# EFR32MG24A020F1536IM40 register map
Vendor: Silicon Labs; Series: EFR32; File version: B
Registers are 32-bit, read-write, reset 0x0 unless marked. A register's access mark holds for its fields unless they carry their own. Offsets are from the block's base; [hi:lo] are bit positions; {n}, {i} and the like mark numbered series; 'fields as' and 'values as' point back to an identical list.

## MODEM_S (part 2 of 2) — MODEM_S Registers
Base 0xA8014000
Same registers: MODEM_NS 0xB8014000
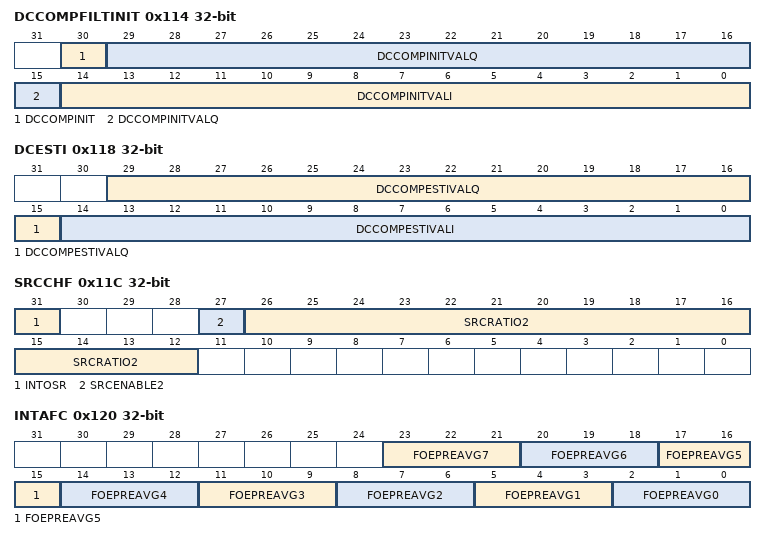
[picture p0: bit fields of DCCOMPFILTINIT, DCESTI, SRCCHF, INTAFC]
0x114 DCCOMPFILTINIT
  [30] DCCOMPINIT — Initialize filter state
  [29:15] DCCOMPINITVALQ — Q-channel initialization value
  [14:0] DCCOMPINITVALI — I-channel initialization value
0x118 DCESTI ro
  [29:15] DCCOMPESTIVALQ — Q-channel DC-Offset Estimated value
  [14:0] DCCOMPESTIVALI — I-channel DC-Offset Estimated value
0x11C SRCCHF
  [31] INTOSR — Forcing Integer OSR
  [27] SRCENABLE2 — SRC2 enable
  [26:12] SRCRATIO2 — SRC2 ratio
0x120 INTAFC
  [23:21] FOEPREAVG7 — Eighth estimate
  [20:18] FOEPREAVG6 — Seventh estimate
  [17:15] FOEPREAVG5 — Sixth estimate
  [14:12] FOEPREAVG4 — Fifth estimate
  [11:9] FOEPREAVG3 — Fourth estimate
  [8:6] FOEPREAVG2 — Third estimate
  [5:3] FOEPREAVG1 — Second estimate
  [2:0] FOEPREAVG0 — First estimate
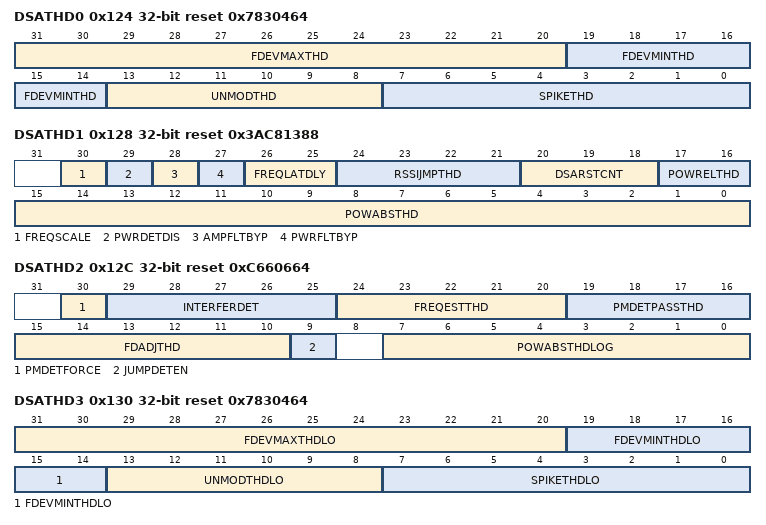
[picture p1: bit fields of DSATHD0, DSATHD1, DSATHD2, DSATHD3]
0x124 DSATHD0 reset 0x7830464
  [31:20] FDEVMAXTHD — Frequency deviation maximum threshold
  [19:14] FDEVMINTHD — Frequency deviation minimum threshold
  [13:8] UNMODTHD — Unmodulated carrier detector threshold
  [7:0] SPIKETHD — Spike threshold
0x128 DSATHD1 reset 0x3AC81388
  [30] FREQSCALE — Frequency scale factor
  [29] PWRDETDIS — Power detection disabled
  [28] AMPFLTBYP — Amplitude filter bypass
  [27] PWRFLTBYP — Power filter bypass
  [26:25] FREQLATDLY — Frequency late delay
  [24:21] RSSIJMPTHD — RSSI jump detector threshold
  [20:18] DSARSTCNT — DSA reset counter
  [17:16] POWRELTHD — Relative power detector threshold
    0=DISABLED (Threshold is 6dB. The relative power detector will trigger when the current RSSI is 6dB stronger than the previously detected RSSI.); 1=MODE1 (Threshold is 9dB. The relative power detector will trigger when the current RSSI is 9dB stronger than the previously detected RSSI.); 2=MODE2 (Threshold is 12dB. The relative power detector will trigger when the current RSSI is 12dB stronger than the previously detected RSSI.); 3=MODE3 (Threshold is 15dB. The relative power detector will trigger when the current RSSI is 15dB stronger than the previously detected RSSI.)
  [15:0] POWABSTHD — Power absolute threshold
0x12C DSATHD2 reset 0xC660664
  [30] PMDETFORCE — Force DSA preamble detector
  [29:25] INTERFERDET — Interference detection threshold
  [24:20] FREQESTTHD — Frequency Estimation Timeout Threshold
  [19:16] PMDETPASSTHD — DSA Preamble detection counter threshold
  [15:10] FDADJTHD — Frequency deviation ripple threshold
  [9] JUMPDETEN — Power jump detection enable
  [7:0] POWABSTHDLOG — Power threshold in logarithm-scale
0x130 DSATHD3 reset 0x7830464
  [31:20] FDEVMAXTHDLO — Frequency deviation maximum threshold
  [19:14] FDEVMINTHDLO — Frequency deviation minimum threshold
  [13:8] UNMODTHDLO — Unmodulated carrier detector threshold
  [7:0] SPIKETHDLO — Spike threshold
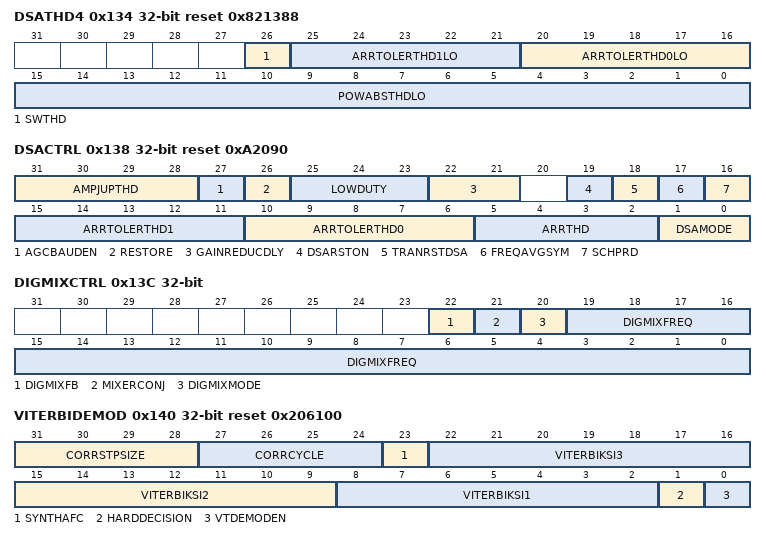
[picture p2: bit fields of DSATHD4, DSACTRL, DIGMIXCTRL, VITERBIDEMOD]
0x134 DSATHD4 reset 0x821388
  [26] SWTHD — Enable switch threshold for low power
  [25:21] ARRTOLERTHD1LO — Arrival tolerance threshold 1
  [20:16] ARRTOLERTHD0LO — Arrival tolerance threshold 0
  [15:0] POWABSTHDLO — Power absolute threshold for low power
0x138 DSACTRL reset 0xA2090
  [31:28] AMPJUPTHD — Amplitude jump detection thrshold
  [27] AGCBAUDEN — Consider Baud_en from AGC
  [26] RESTORE — Power detector reset of DSA
  [25:23] LOWDUTY — Low duty cycle delay
  [22:21] GAINREDUCDLY — Detection Delay of AGC gain reduction
  [19] DSARSTON — DSA detection reset
  [18] TRANRSTDSA — power transient detector Reset DSA
  [17] FREQAVGSYM — DSA frequency estimation averaging
    0=AVG2TS (Frequency estimation over 2 symbol periods.); 1=AVG4TS (Frequency estimation over 4 symbol periods.)
  [16] SCHPRD — Search period window length
    0=TS2 (The search period is 2 symbol periods.); 1=TS4 (The search period is 4 symbol periods.)
  [15:11] ARRTOLERTHD1 — Arrival tolerance threshold 1
  [10:6] ARRTOLERTHD0 — Arrival tolerance threshold 0
  [5:2] ARRTHD — Signal arrival valid counter threshold
  [1:0] DSAMODE — Mode of Digital Signal Arrival detector
    0=DISABLED (DSA is disabled); 1=ENABLED (DSA is enabled by the relative/absolute RSSI detector and is reset by using detectors for spike content and frequency deviation. The RSSI jump detector is used to recover from false detects.)
0x13C DIGMIXCTRL
  [22] DIGMIXFB — Digital mixer Frequency Correction
  [21] MIXERCONJ — Digital mixer input conjugate
  [20] DIGMIXMODE — Digital mixer frequency control
    0=CFOSR (Mixer frequency specified by CFOSR.); 1=DIGMIXFREQ (Mixer frequency specified by DIGMIXFREQ.)
  [19:0] DIGMIXFREQ — Digital mixer frequency control word
0x140 VITERBIDEMOD reset 0x206100
  [31:28] CORRSTPSIZE — Correction step size
  [27:24] CORRCYCLE — Correction cycles
  [23] SYNTHAFC — Synthesizer AFC in Viterbi demod
  [22:16] VITERBIKSI3
  [15:9] VITERBIKSI2
  [8:2] VITERBIKSI1
  [1] HARDDECISION
  [0] VTDEMODEN — Viterbi demodulator enable
0x144 VTCORRCFG0 reset 0x123556B7
  [31:0] EXPECTPATT — Expected pattern
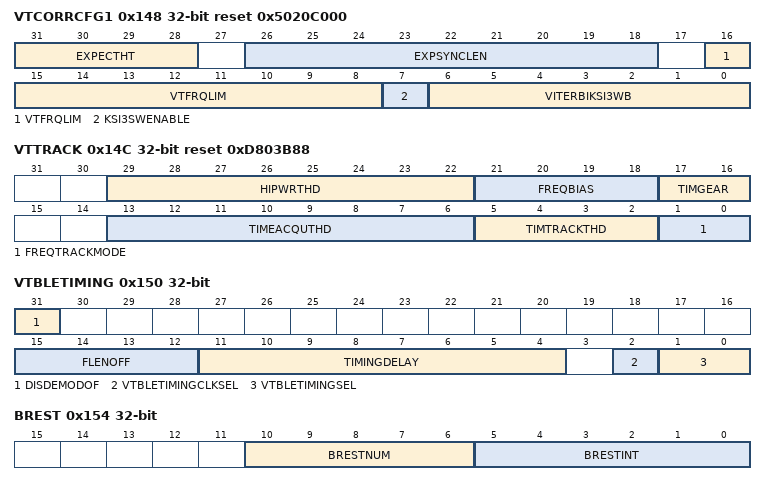
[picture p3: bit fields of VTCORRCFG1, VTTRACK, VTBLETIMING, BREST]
0x148 VTCORRCFG1 reset 0x5020C000
  [31:28] EXPECTHT — Expected patterns head and tail
  [26:18] EXPSYNCLEN — Expected sync length
  [16:8] VTFRQLIM — Viterbi frequency limiter
  [7] KSI3SWENABLE — WB KSI3 Switching Enable
  [6:0] VITERBIKSI3WB — WB KSI3
0x14C VTTRACK reset 0xD803B88
  [29:22] HIPWRTHD — High Power detection threshold
  [21:18] FREQBIAS — Frequency estimation bias
  [17:16] TIMGEAR — Timing Gear
    0=GEAR0 (Execute timing tracking regardless of difference between Early/Late and Current correlation values. Referred to as fast gear. Same as GEAR3); 1=GEAR1 (Execute timing tracking only when correlation value of Early/Late is 75% or less of the Current correlation value. Referred to as medium gear.); 2=GEAR2 (Execute timing tracking only when correlation value of Early/Late is 50% or less of the Current correlation value. Referred to as slow gear.)
  [13:6] TIMEACQUTHD — Time acquisition threshold
  [5:2] TIMTRACKTHD — Timing tracking threshold
  [1:0] FREQTRACKMODE — Frequency tracking mode
    0=DISABLED (Frequency tracking disabled. Only a one-time frequency offset compensation applied through DSA.); 1=MODE1 (Frequency tracking enabled with one correction, when needed, every 16 symbol periods.); 2=MODE2 (Frequency tracking enabled with one correction, when needed, every 32 symbol periods.); 3=MODE3 (Frequency tracking enabled with one correction, when needed, every 48 symbol periods.)
0x150 VTBLETIMING
  [31] DISDEMODOF — Disable VT Demod Over Flow Detection
  [15:12] FLENOFF — Timing Stamp Frame Length Offset
  [11:4] TIMINGDELAY — Viterbi BLE Delay timer
  [2] VTBLETIMINGCLKSEL — Viterbi BLE timing stamp clock select
  [1:0] VTBLETIMINGSEL — Viterbi BLE timing stamp selection
    0=FRAMEDET_DELAY (Delayed frame detection will be used as Timing stamp. This mode should be selected for legacy demod and Long Range BLE demod.); 1=END_FRAME_PULSE (The end of frame detection from Narrow Viterbi demod will be used as Timing stamp. This signal is a narrow pulse signal and pulse width is one xo clock cycle.); 2=END_FRAME (The end of frame detection from Narrow Viterbi demod will be used as Timing stamp. This signal is a wdie pulse signal); 3=INV_END_FRAME (For testing only.)
0x154 BREST ro
  [10:6] BRESTNUM — Fractional part of estimated baudrate
  [5:0] BRESTINT — Integer part of estimated baudrate
0x158 AUTOCG
  [15:0] AUTOCGEN — Enable automatic clock gating
0x15C CGCLKSTOP
  [15:0] FORCEOFF — Manual control clocks
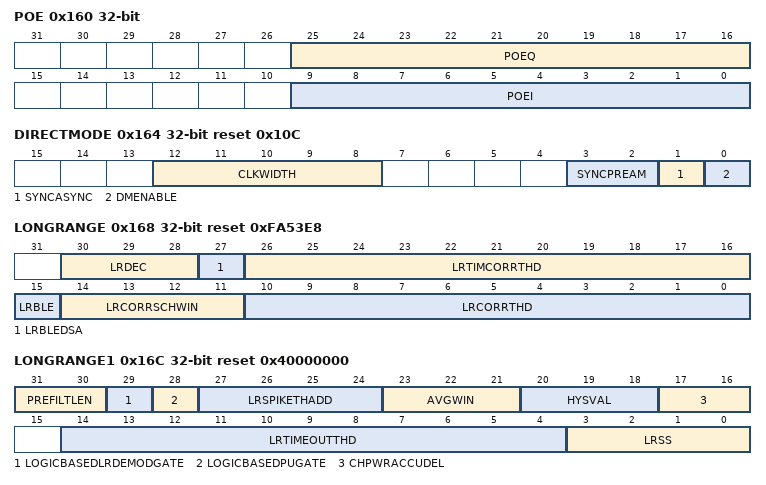
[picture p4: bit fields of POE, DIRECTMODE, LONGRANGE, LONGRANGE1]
0x160 POE ro
  [25:16] POEQ — Quadrature component of POE.
  [9:0] POEI — In-phase component of POE.
0x164 DIRECTMODE reset 0x10C
  [12:8] CLKWIDTH — Synchronous mode clock pulse width
  [3:2] SYNCPREAM — Synchronous mode preamble
    0=ADD0 (No preamble bits appended); 1=ADD8 (8 preamble bits appended); 2=ADD16 (16 preamble bits appended); 3=ADD32 (32 preamble bits appended)
  [1] SYNCASYNC — Choose Synchronous or Asynchronous mode
  [0] DMENABLE — Enable Direct Mode
0x168 LONGRANGE reset 0xFA53E8
  [30:28] LRDEC — DEC value
  [27] LRBLEDSA — DSA enable
  [26:16] LRTIMCORRTHD — Correlator threshold
  [15] LRBLE — Enable
  [14:11] LRCORRSCHWIN — Window size
  [10:0] LRCORRTHD — Correlator threshold
0x16C LONGRANGE1 reset 0x40000000
  [31:30] PREFILTLEN — Prefilter Length
    0=LEN32 (Filter length is 32); 1=LEN64 (Filter length is 64); 2=LEN96 (Filter length is 96); 3=LEN128 (Filter length is 128)
  [29] LOGICBASEDLRDEMODGATE — Logic Based Long Range Demod Gating
  [28] LOGICBASEDPUGATE — Logic Based Phase Unwrap Gating
  [27:24] LRSPIKETHADD — Long Range DSA spike threshold addition
  [23:21] AVGWIN — Average window
  [20:18] HYSVAL — Hysteresis Value for BBSS
  [17:16] CHPWRACCUDEL — Channel Power Accumulated Delay
    0=DEL0 (Use accumulated channel power value); 1=DEL32 (Delayed by 32 chips); 2=DEL64 (Delayed by 64 chips)
  [14:4] LRTIMEOUTTHD — Long Range Time Out Threshold
  [3:0] LRSS — Long Range Signal Selection
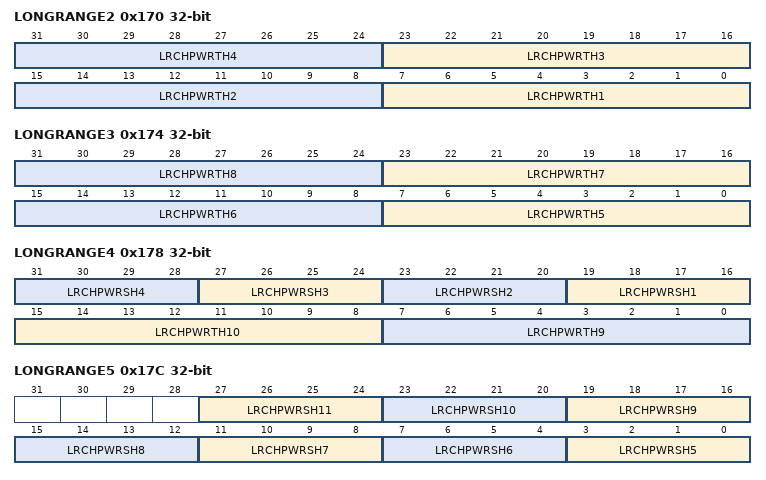
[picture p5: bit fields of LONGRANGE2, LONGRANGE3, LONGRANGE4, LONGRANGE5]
0x170 LONGRANGE2
  [8n-1:8n-8] LRCHPWRTH{n} (n=1..4) — Long Range channel power threshold
0x174 LONGRANGE3
  [8n-33:8n-40] LRCHPWRTH{n} (n=5..8) — Long Range channel power threshold
0x178 LONGRANGE4
  [4n+15:4n+12] LRCHPWRSH{n} (n=1..4) — Long Range channel power shift
  [15:8] LRCHPWRTH10 — Long Range channel power threshold
  [7:0] LRCHPWRTH9 — Long Range channel power threshold
0x17C LONGRANGE5
  [4n-17:4n-20] LRCHPWRSH{n} (n=5..11) — Long Range channel power shift
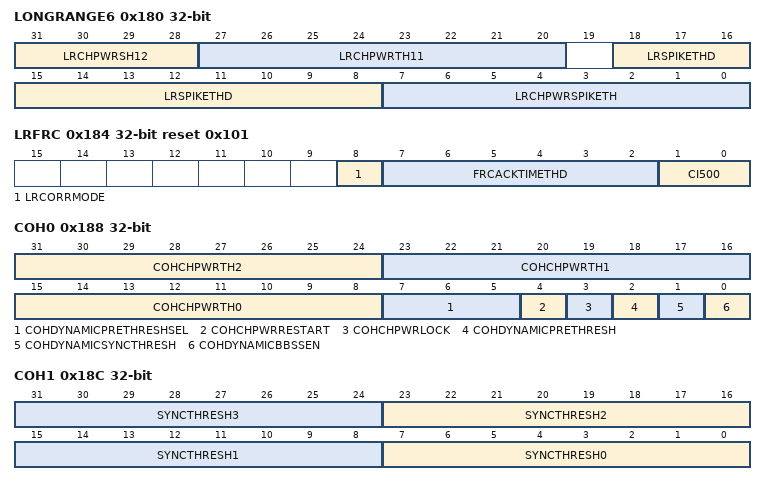
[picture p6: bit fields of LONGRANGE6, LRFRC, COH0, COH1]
0x180 LONGRANGE6
  [31:28] LRCHPWRSH12 — Long Range channel power shift
  [27:20] LRCHPWRTH11 — Long Range channel power threshold
  [18:8] LRSPIKETHD — Long Range spike threshold
  [7:0] LRCHPWRSPIKETH — Long Range channel power spike threshold
0x184 LRFRC reset 0x101
  [8] LRCORRMODE — LR Correlator operation Mode
  [7:2] FRCACKTIMETHD — FRC acknowledge timeout threshold
  [1:0] CI500 — Long Range CI mapping for 500kbps
0x188 COH0
  [31:24] COHCHPWRTH2 — Channel power threshold
  [23:16] COHCHPWRTH1 — Channel power threshold
  [15:8] COHCHPWRTH0 — Channel power threshold
  [7:5] COHDYNAMICPRETHRESHSEL — Dynamic preamble threshold selection
    0=SEL0 (1x sync coeff); 1=SEL1 (0.94x sync coeff); 2=SEL2 (0.88x sync coeff); 3=SEL3 (0.74x sync coeff); 4=SEL4 (0.5x sync coeff)
  [4] COHCHPWRRESTART — Channel power restart
  [3] COHCHPWRLOCK — Channel power lock
    0=TIMDET (Channel power locked when timing is detected); 1=DSADET (Channel power locked when DSA is detected)
  [2] COHDYNAMICPRETHRESH — Dynamic preamble threshold enable bit
  [1] COHDYNAMICSYNCTHRESH — Dynamic syncword threshold enable bit
  [0] COHDYNAMICBBSSEN — Dynamic BBSS enable bit
0x18C COH1
  [8n+7:8n] SYNCTHRESH{n} (n=0..3) — Minimum correlation threshold
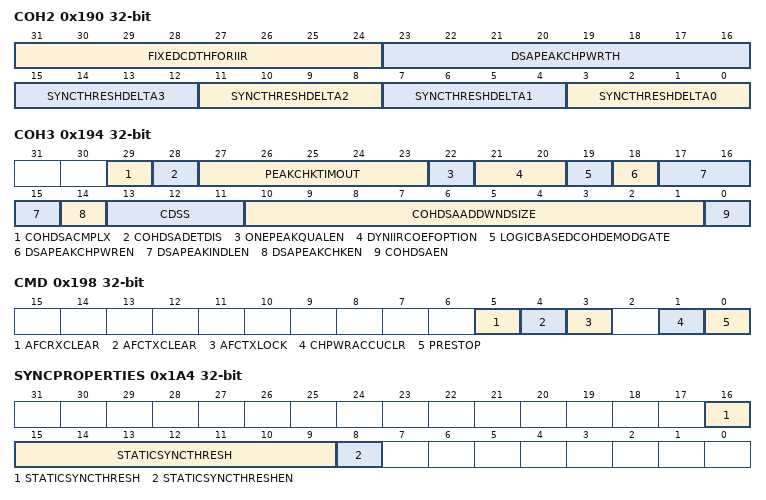
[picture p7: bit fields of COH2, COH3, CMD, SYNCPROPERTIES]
0x190 COH2
  [31:24] FIXEDCDTHFORIIR
  [23:16] DSAPEAKCHPWRTH — DSA Peak Check CHpwr Threshold
  [4n+3:4n] SYNCTHRESHDELTA{n} (n=0..3) — Syncword correlation delta threshold
0x194 COH3
  [29] COHDSACMPLX — DSA Complex
  [28] COHDSADETDIS — DSA Detection Disable
  [27:23] PEAKCHKTIMOUT — Peak Check Time Out
  [22] ONEPEAKQUALEN — One Peak
  [21:20] DYNIIRCOEFOPTION — Dynamic IIR
  [19] LOGICBASEDCOHDEMODGATE — Logic Based clock gate
  [18] DSAPEAKCHPWREN — DSA Peak Check channel power enable
  [17:15] DSAPEAKINDLEN — DSA Peak Index length
  [14] DSAPEAKCHKEN — DSA Peak Checking Enable
  [13:11] CDSS — DSA Signal Selection
  [10:1] COHDSAADDWNDSIZE — DSA additional window size
  [0] COHDSAEN — DSA enable bit
0x198 CMD wo
  [5] AFCRXCLEAR — Clear AFC RX compensation.
  [4] AFCTXCLEAR — Clear AFC TX compensation.
  [3] AFCTXLOCK — Lock AFC TX compensation
  [1] CHPWRACCUCLR — Channel Power Accumulation Clear
  [0] PRESTOP — Preamble stop
0x1A4 SYNCPROPERTIES
  [16:9] STATICSYNCTHRESH — Static Sync Threshold
  [8] STATICSYNCTHRESHEN — Static Sync Threshold Enable
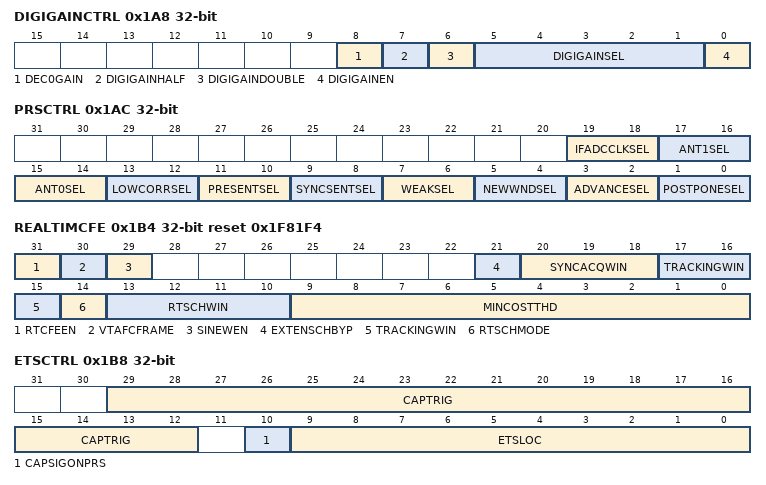
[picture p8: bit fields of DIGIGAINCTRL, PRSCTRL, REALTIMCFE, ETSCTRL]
0x1A8 DIGIGAINCTRL
  [8] DEC0GAIN — DEC0 Gain Select
  [7] DIGIGAINHALF — Digital Gain Halved
  [6] DIGIGAINDOUBLE — Digital Gain Doubled
  [5:1] DIGIGAINSEL — Digital Gain Select
    0=GAINM3; 1=GAINM2P75; 2=GAINM2P5; 3=GAINM2P25; 4=GAINM2; 5=GAINM1P75; 6=GAINM1P5; 7=GAINM1P25; 8=GAINM1; 9=GAINM0P75; 10=GAINM0P5; 11=GAINM0P25; 12=GAINM0; 13=GAINP0P25; 14=GAINP0P5; 15=GAINP0P75; 16=GAINP1; 17=GAINP1P25; 18=GAINP1P5; 19=GAINP1P75; 20=GAINP2; 21=GAINP2P25; 22=GAINP2P5; 23=GAINP2P75; 24=GAINP3
  [0] DIGIGAINEN — Digital Gain Enable
0x1AC PRSCTRL
  [19:18] IFADCCLKSEL, [17:16] ANT1SEL, [15:14] ANT0SEL, [13:12] LOWCORRSEL, [11:10] PRESENTSEL, [9:8] SYNCSENTSEL, [7:6] WEAKSEL, [5:4] NEWWNDSEL, [3:2] ADVANCESEL, [1:0] POSTPONESEL
0x1B4 REALTIMCFE reset 0x1F81F4
  [31] RTCFEEN — TRECS Enable
  [30] VTAFCFRAME — Viterbi AFC FRAME Mode
  [29] SINEWEN — Enable SINE WEIGHT
  [21] EXTENSCHBYP — Bypass extending Search Time
  [20:18] SYNCACQWIN — SYNC Correlator Size
  [17:15] TRACKINGWIN — Correlator size for Tracking
  [14] RTSCHMODE — Real Time CFE searching mode
  [13:10] RTSCHWIN — Real time CFE searching window
  [9:0] MINCOSTTHD — Min. Cost thrshold
0x1B8 ETSCTRL
  [29:12] CAPTRIG — Trigger to capture
  [10] CAPSIGONPRS — Capture Signal On PRS
  [9:0] ETSLOC — Early Time Stamp Location
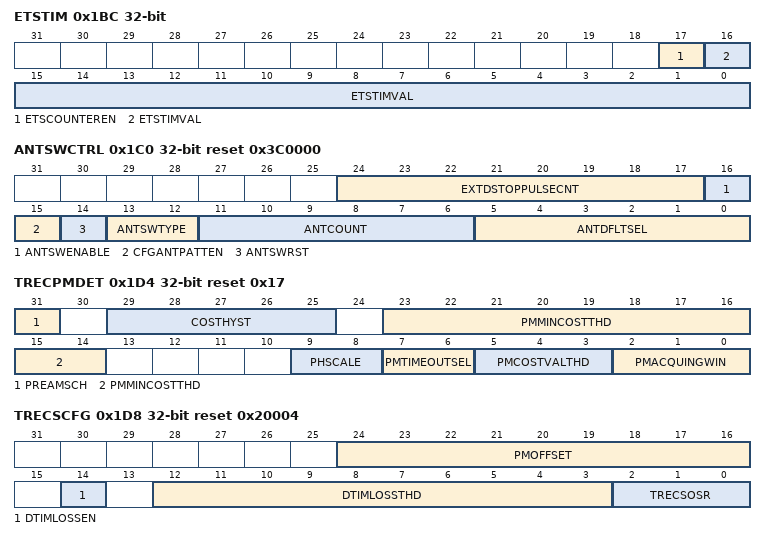
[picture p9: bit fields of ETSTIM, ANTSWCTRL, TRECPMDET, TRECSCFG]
0x1BC ETSTIM
  [17] ETSCOUNTEREN, [16:0] ETSTIMVAL
0x1C0 ANTSWCTRL reset 0x3C0000
  [24:17] EXTDSTOPPULSECNT — Extend Stop Pulse Counter
  [16] ANTSWENABLE
  [15] CFGANTPATTEN — Configure Ant Pattern Enable
  [14] ANTSWRST wo — Ant SW rst pulse
  [13:12] ANTSWTYPE — Ant Switch Type
    0=US_2 (2us ant switching); 1=US_4 (4us ant switching); 2=US_6 (6us ant switching); 3=US_8 (8us ant switching)
  [11:6] ANTCOUNT — Total Ant count
  [5:0] ANTDFLTSEL — Ant Default Select
0x1C4 ANTSWCTRL1 reset 0x6AAAA
  [23:0] TIMEPERIOD — Time Period of xtal
0x1C8 ANTSWSTART
  [17:0] ANTSWSTARTTIM — Ant switch start time
0x1CC ANTSWEND
  [17:0] ANTSWENDTIM — Ant switch start time
0x1D0 TRECPMPATT reset 0x55555555
  [31:0] PMEXPECTPATT — Expected PM pattern
0x1D4 TRECPMDET reset 0x17
  [31] PREAMSCH — PM detection enable in TRECS
  [29:25] COSTHYST — PM Seaching COST HYST
  [23:14] PMMINCOSTTHD — Min. Cost thrshold for TRECS PM
  [9:8] PHSCALE — PHASE Scaler
  [7:6] PMTIMEOUTSEL — PM searching timeout Threshold
  [5:3] PMCOSTVALTHD — Min COST Validation for AFC
  [2:0] PMACQUINGWIN — PM Correlator Size
0x1D8 TRECSCFG reset 0x20004
  [24:16] PMOFFSET — PM SCH ADRESS offsrt
  [14] DTIMLOSSEN — ENABLE TIMING LOSS DETECTION
  [12:3] DTIMLOSSTHD — Timing Loss Threshold
  [2:0] TRECSOSR
0x1DC CFGANTPATT
  [29:0] CFGANTPATTVAL
0x1E0 COCURRMODE
  [31] CONCURRENT — CONCURRENT MODE Enable
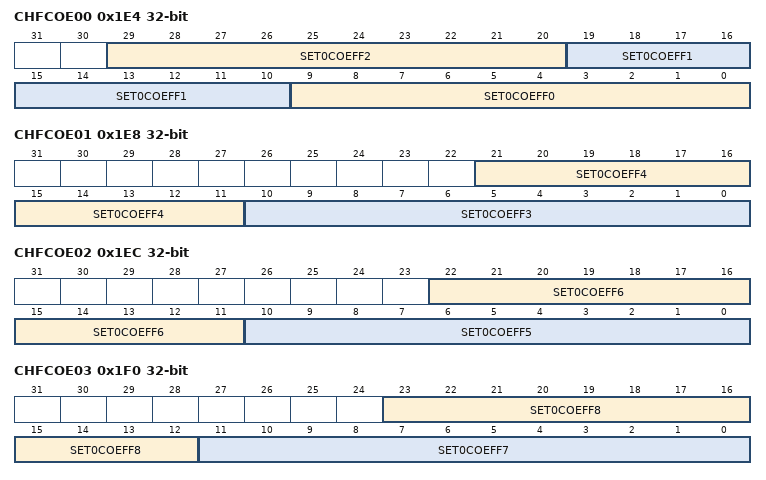
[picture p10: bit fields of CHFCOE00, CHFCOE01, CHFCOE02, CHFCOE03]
0x1E4 CHFCOE00
  [29:20] SET0COEFF2 — SET 0 CHF COE2
  [19:10] SET0COEFF1 — SET 0 CHF COE1
  [9:0] SET0COEFF0 — SET 0 CHF COE0
0x1E8 CHFCOE01
  [21:11] SET0COEFF4 — SET 0 CHF COE4
  [10:0] SET0COEFF3 — SET 0 CHF COE3
0x1EC CHFCOE02
  [22:11] SET0COEFF6 — SET 0 CHF COE6
  [10:0] SET0COEFF5 — SET 0 CHF COE5
0x1F0 CHFCOE03
  [23:12] SET0COEFF8 — SET 0 CHF COE8
  [11:0] SET0COEFF7 — SET 0 CHF COE7
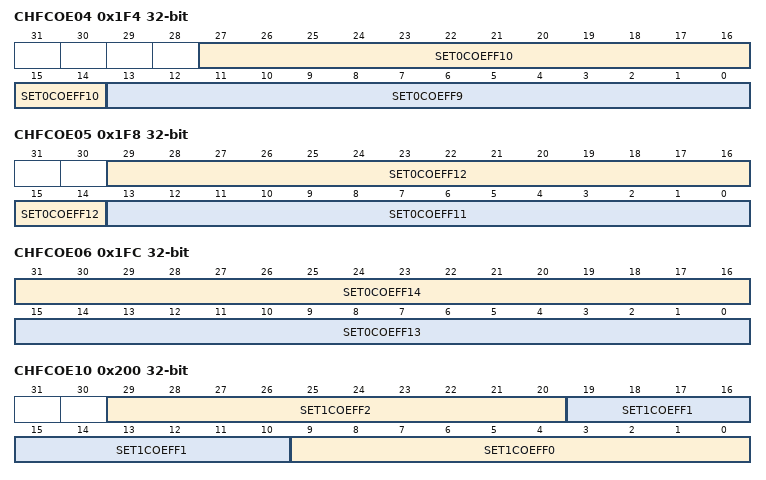
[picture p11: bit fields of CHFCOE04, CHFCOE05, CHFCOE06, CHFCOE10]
0x1F4 CHFCOE04
  [27:14] SET0COEFF10 — SET 0 CHF COE10
  [13:0] SET0COEFF9 — SET 0 CHF COE9
0x1F8 CHFCOE05
  [29:14] SET0COEFF12 — SET 0 CHF COE12
  [13:0] SET0COEFF11 — SET 0 CHF COE11
0x1FC CHFCOE06
  [31:16] SET0COEFF14 — SET 0 CHF COE14
  [15:0] SET0COEFF13 — SET 0 CHF COE13
0x200 CHFCOE10
  [29:20] SET1COEFF2 — SET 1 CHF COE2
  [19:10] SET1COEFF1 — SET 1 CHF COE1
  [9:0] SET1COEFF0 — SET 1 CHF COE0
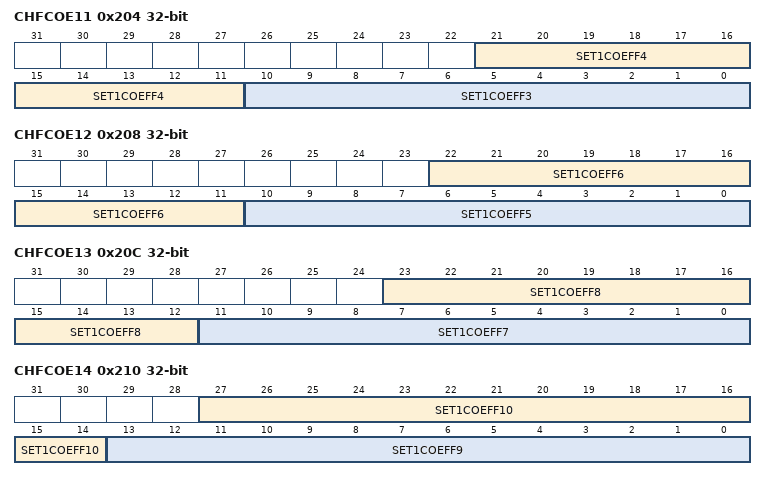
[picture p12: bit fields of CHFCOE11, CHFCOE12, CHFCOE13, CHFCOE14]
0x204 CHFCOE11
  [21:11] SET1COEFF4 — SET 1 CHF COE4
  [10:0] SET1COEFF3 — SET 1 CHF COE3
0x208 CHFCOE12
  [22:11] SET1COEFF6 — SET 1 CHF COE6
  [10:0] SET1COEFF5 — SET 1 CHF COE5
0x20C CHFCOE13
  [23:12] SET1COEFF8 — SET 1 CHF COE8
  [11:0] SET1COEFF7 — SET 1 CHF COE7
0x210 CHFCOE14
  [27:14] SET1COEFF10 — SET 1 CHF COE10
  [13:0] SET1COEFF9 — SET 1 CHF COE9
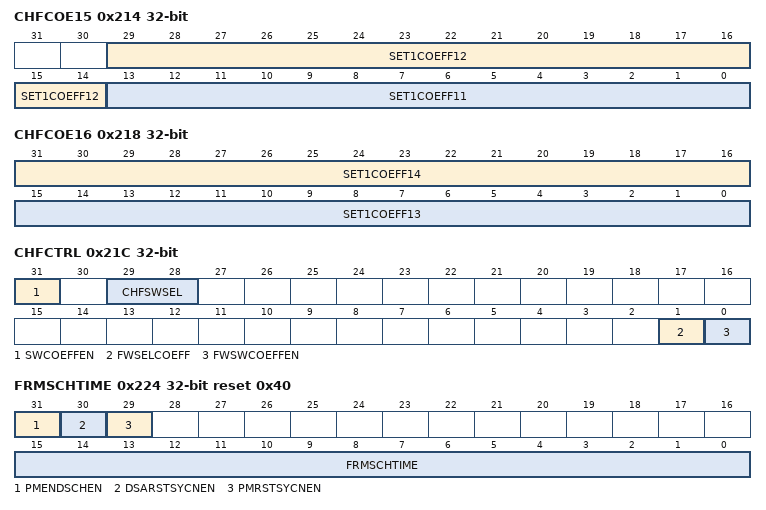
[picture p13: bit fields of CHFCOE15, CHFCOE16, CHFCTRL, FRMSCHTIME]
0x214 CHFCOE15
  [29:14] SET1COEFF12 — SET 1 CHF COE12
  [13:0] SET1COEFF11 — SET 1 CHF COE11
0x218 CHFCOE16
  [31:16] SET1COEFF14 — SET 1 CHF COE14
  [15:0] SET1COEFF13 — SET 1 CHF COE13
0x21C CHFCTRL
  [31] SWCOEFFEN — Switch CHF COE. Enable
  [29:28] CHFSWSEL — Channel filter switch selection
    0=PREDET (When swcoeffen == 1, use demod_predet to select coefficient set); 1=FRC_SUP (Use ctecoeset when in RX_SUP, coefficient set 0 otherwise); 2=CHFSWTRIG (Use the timer CHFSWTRIG to select the coefficient set, set 0 otherwise); 3=INVALID (Coefficient set 0)
  [1] FWSELCOEFF — FW Select CHF COE. set
  [0] FWSWCOEFFEN — FW Switch CHF COE. Enable
0x220 CHFLATENCYCTRL
  [1:0] CHFLATENCY
0x224 FRMSCHTIME reset 0x40
  [31] PMENDSCHEN — EnABLE SCH PM END
  [30] DSARSTSYCNEN — ENABLE CLEAN SYNC
  [29] PMRSTSYCNEN — ENABLE CLEAN SYNC
  [15:0] FRMSCHTIME — FRAME SCH TIME OUT THRD
0x228 PREFILTCOEFF reset 0x3B3B3B3B
  [31:0] PREFILTCOEFF — Preamble Filter Coefficients
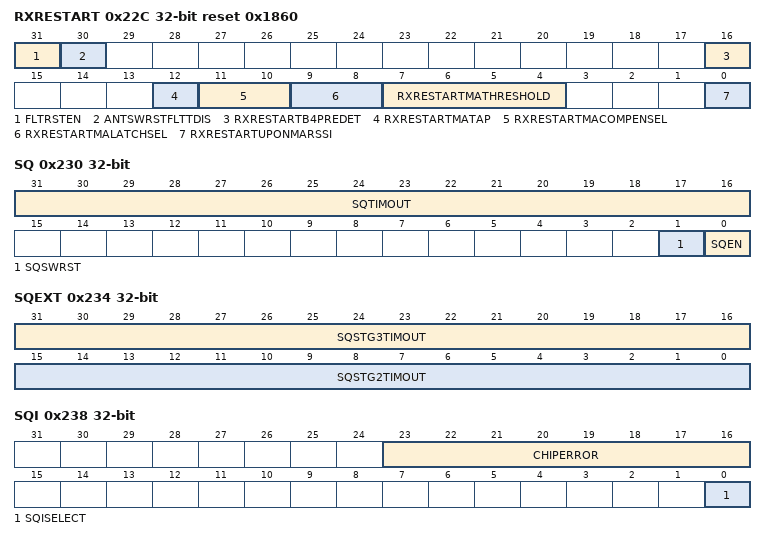
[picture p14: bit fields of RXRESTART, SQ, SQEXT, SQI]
0x22C RXRESTART reset 0x1860
  [31] FLTRSTEN — RX Chain Filter reset enable
  [30] ANTSWRSTFLTTDIS — ANT SW RESET Filter Disable
  [16] RXRESTARTB4PREDET — whether to restart RX before pre det
  [12] RXRESTARTMATAP — Number of taps for the MA filter
    0=TAPS4; 1=TAPS8
  [11:10] RXRESTARTMACOMPENSEL — Enable the comparator
    0=PRE_DET (preamble detection); 1=FRAME_SYNC_DET (frame/sync detection); 2=BOTH1 (both preamble and frame/sync detection); 3=BOTH2 (both preamble and frame/sync detection)
  [9:8] RXRESTARTMALATCHSEL — latch the RSSI MA filter output
    0=RE_PRE_DET (rising edge of per det); 1=RE_SYNC_DET (rising edge of sync det); 2=EITHER1 (either of the two); 3=EITHER2 (either of the two)
  [7:4] RXRESTARTMATHRESHOLD — Threshold for the RSSI MA filter
    {v}=DB{v} ({v} DB) (v=0..4); 5=DB5; 6=DB6 (6 DB); {v}=DB{v} (v=7..14); 15=DB15 (15 DB)
  [0] RXRESTARTUPONMARSSI — Restart RX upon RSSI MA above threshold
0x230 SQ
  [31:16] SQTIMOUT — SQ Timeout
  [1] SQSWRST wo — SQ hold demod
  [0] SQEN — SQ enable
0x234 SQEXT
  [31:16] SQSTG3TIMOUT — SQ Timeout
  [15:0] SQSTG2TIMOUT — SQ Timeout
0x238 SQI
  [23:16] CHIPERROR ro — Chip errors
  [0] SQISELECT — SQI selection bit
    0=CORR; 1=ERROR
0x23C ANTDIVCTRL
  [10] ANTDIVSELCCA — Antenna switch selection for CSMA
  [9] ANTDIVDISCCA — Antenna switch disable for CSMA
  [8] ENADPRETHRESH — Enable Preamble threshold
    0=DISABLE (Disable use of Preamble threshold after timing detection); 1=ENABLE (Enable use of Preamble threshold after timing detection)
  [7:0] ADPRETHRESH — Preamble threshold
0x240 ANTDIVFW
  [31] FWANTDIVEN — Enable FW ANT-DIV mode
  [1] FWANTSWCMD wo — FW Antenna SW cmd
  [0] FWSELANT — FW antenna selection
0x244 PHDMODANTDIV reset 0xF
  [30] SKIP2ANT — SKIP 2th ANTENNA Evaluate
  [23:16] SKIPCORRTHD — CORR THD to SKIP 2th ANTENNA Evaluate
  [12:5] SKIPRSSITHD — RSSI THD to SKIP 2th ANTENNA Evaluate
  [4:0] ANTWAIT — ANTENNA WAIT TIME
0x248 PHANTDECSION
  [n+28] RSSICORR{n} (n=0..3) — RSSI-CORR Selection in Region{n}
  [18:10] RSSIANDDIVTHD — RSSI Selection in region
  [9:0] CORRANDDIVTHD — Correlation Selection in region
0x24C PHDMODCTRL reset 0x1DF0004
  [31] BCRLEGACYCONC — BCR/TRECS CONCURRENT MODE
  [30] BCRTRECSCONC — BCR/LEGACY CONCURRENT MODE
  [29] BCRDETECTOR — Enbale BCRDMOD Dtetector ONLY
  [28] REMODEN — REMOD ENABLE
  [27:26] REMODOUTSEL — REMOD OUTPUT Selection
  [25:22] REMODDWN — REMOD downsampling ratio
  [21:16] REMODOSR — REMOD INPUT OSR
  [15] PMDETEN — PREAMBLE DET
  [14] RSSIFLTBYP — Bypass RSSI Filering
  [13] PMTIMLOSEN — Preamble timing loss detection
  [12:5] PMTIMLOSTHD — Preamble Timing loss thrshold
  [4:0] PMDETTHD — Preamble Detection Thrshould
0x250 SICTRL0
  [29:23] FREQNOMINAL — Freq nominal number
  [22:18] SMALLSAMPLETHRESH — Small sample threshold
  [17:15] PEAKNUMTHRESHSW — Peak number threshold short window
  [14:10] PEAKNUMTHRESHLW — Peak number threshold long window
  [9:2] NOISETHRESH — Noise threshold
  [1:0] MODE — Signal Identifier Mode
    0=DISABLE (Signal identifier feature disable.); 1=ZB (Zigbee detection mode); 2=BLE2 (BLE2 detection mode); 3=BLE1 (BLE1 detection mode)
0x254 SICTRL1
  [31:27] NARROWPULSETHRESH — Narrow pulse threshold
  [26] FASTMODE — Zigbee fast mode
  [25:23] CORRNUM — Correlation over threshold number
  [22:12] CORRTHRESH — Correlator threshold
  [11:5] SUPERCHIPMEDIAN — Superchip freq dev median value
  [4:0] SUPERCHIPTOLERANCE — Superchip freq dev tolerance
0x258 SISTATUS ro
  [30] SIDET — Signal detected
  [29] SNIFFDONE
  [26:21] CORRPASSNUM — CORR success num
  [20:18] TIMEOFFSET — Timing offset
  [17] SUPERCHIPPASS
  [16] SUPERCHIPFAIL
  [15] TIMELOCK — Timing locked
  [14:10] NARROWCOUNT — Narrow pulse count
  [9:5] LWPEAKCOUNT — Peak count
  [4] NOISE — Noisy short window
  [3:0] SISTATE — SI main FSM
0x25C CFGANTPATTEXT
  [29:0] CFGANTPATTVALEXT — extra CFGANTPATTVAL
0x264 SICTRL2
  [7] AGCRSTUPONSI — AGC reset on SI reset
  [6] DISSIFRAMEDET — Disable SI when framedet
  [5:3] SUPERCHIPTHRESH — Superchip pass threshold
  [2] SIRSTCCAMODE — SI reset by CCA req
  [1] SIRSTPRSMODE — SI reset by PRS PAEN
  [0] SIRSTAGCMODE — SI reset by AGC
0x268 CHFSWCTRL
  [17:0] CHFSWTIME — Channel Filter Switch Time
0x270 IRCAL
  [15] IRCALIFADCDBG
  [14] IRCALCOEFRSTCMD wo — IRCAL coef reset cmd
  [13] IRCORREN — IR Correction enable bit
  [12:7] MUISHF — MUI shift value
  [5:1] MURSHF — MUR shift value
  [0] IRCALEN — IRCAL enable bit
0x274 IRCALCOEF ro
  [30:16] CIV — CIV coefficient
  [14:0] CRV — CRV coefficient
0x278 IRCALCOEFWR0
  [31] CIVWEN — CIV Coefficient Write Enable
  [30:16] CIVWD — CIV coefficient
  [15] CRVWEN — CIV Coefficient Write Enable
  [14:0] CRVWD — CRV coefficient
0x27C IRCALCOEFWR1
  fields as IRCALCOEFWR0
0x280 ADCTRL1 reset 0x80000
  [31:0] ADCTRL1 — AD control
0x284 ADCTRL2 reset 0x1
  [31:0] ADCTRL2 — ADPC control
0x288 ADQUAL0 ro
  [25:16] ADRSSI1 — ANT1 RSSI
  [9:0] ADRSSI0 — ANT0 RSSI
0x28C ADQUAL1 ro
  [31:17] ADSTAT1
  [16:0] ADCORR0 — ANT0 CORR
0x290 ADQUAL2 ro
  [25:16] ADRSSI1P — Previous ANT1 RSSI
  [9:0] ADRSSI0P — Previous ANT0 RSSI
0x294 ADQUAL3 ro
  [31:17] ADSTAT2
  [16:0] ADCORR0P — Previous ANT0 CORR
0x298 ADQUAL4 reset 0x200003F
  [31:30] ADGRMODE — Gain reduced mode
  [25:16] ADRSSIGRTHR — RSSI gain reduced threshold
  [5:0] ADAGCGRTHR — AGC gain reduced threshold
0x29C ADQUAL5 reset 0xFFFF
  [16:0] ADDIRECTCORR — AD direct selection correlation
0x2A0 ADQUAL6 reset 0xFFFF
  [31:17] ADBACORRDIFF — AD best antenna correlation diff
  [16:0] ADBACORRTHR — AD best antenna correlation thr
0x2A4 ADQUAL7 reset 0x3FF
  [25:16] ADBARSSIDIFF — AD best antenna RSSI diff
  [9:0] ADBARSSITHR — AD best antenna RSSI thr
0x2A8 ADQUAL8 reset 0xFFFF
  [29:24] ADBAAGCTHR — AD best antenna AGC thr
  [21:20] ADBAMODE — AD best antenna mode
  [16:0] ADBACORRTHR2 — AD best antenna correlation thr2
0x2AC ADQUAL9 ro
  [16:0] ADCORR1 — ANT1 CORR
0x2B0 ADQUAL10 ro
  [16:0] ADCORR1P — Previous ANT1 CORR
0x2B4 ADFSM0
  [30:26] ADSTAT2SEL
  [25:21] ADSTAT1SEL
  [20] ADSTATREAD
  [19] ADTD1P ro — timdet1p
  [18] ADTD1 ro — timdet1
  [17] ADTD0P ro — timdet0p
  [16] ADTD0 ro — timdet0
  [15:12] ADSTATEN ro — Next AD state
  [11:8] ADSTATEP2 ro — 2nd previous AD state
  [7:4] ADSTATEP ro — Previous AD state
  [3:0] ADSTATEC ro — Current AD state
0x2B8 ADFSM1
  [31:16] ADOSETANT1 — AD output mux
  [15:0] ADOSETANT0 — AD output mux
0x2BC ADFSM2
  [31:16] ADORESTARTRX — AD output mux
  [15:0] ADOSWITCHANT — AD output mux
0x2C0 ADFSM3
  [31:16] ADOQUAL1UPDATE — AD output mux
  [15:0] ADOQUAL0UPDATE — AD output mux
0x2C4 ADFSM4
  [31:16] ADOQUAL1CLEAR — AD output mux
  [15:0] ADOQUAL0CLEAR — AD output mux
0x2C8 ADFSM5
  [31:0] ADOMUX — AD output mux
{0x2B4+4i} ADFSM{i} (i=6..13)
  [31:16] ADNEXTSTATESW{2i-11} — AD next states
  [15:0] ADNEXTSTATESW{2i-12} — AD next states
0x2EC ADFSM14
  [31:16] ADFSMCOND1ENA — AD next states
  [15:0] ADFSMCOND0ENA — AD next states
0x2F0 ADFSM15
  [31:16] ADFSMCOND3ENA — AD next states
  [15:0] ADFSMCOND2ENA — AD next states
0x2F4 ADFSM16
  [31:16] ADFSMCOND1ENB — AD next states
  [15:0] ADFSMCOND0ENB — AD next states
0x2F8 ADFSM17
  [31:16] ADFSMCOND3ENB — AD next states
  [15:0] ADFSMCOND2ENB — AD next states
0x2FC ADFSM18
  [31:0] ADFSMCONDSEL — AD next states
0x300 ADFSM19
  [31:16] ADFSMCONDTRUE — AD next states
  [15:0] ADFSMNEXTFORCE — AD next states
0x304 ADFSM20
  [31:16] ADITLEAVEEN — AD FSM IT leave enable
  [15:0] ADITENTEREN — AD FSM IT enter enable
0x308 ADFSM21
  [16] ADUNFREEZE wo — AD FSM unfreeze
  [8] ADBA ro — best_antenna
  [7] ADAS ro — antsel
  [6:3] ADUNFREEZENEXT — AD FSM unfreeze next state
  [2] ADFROZEN ro — AD FSM frozen
  [1] ADLEAVEFREEZEEN — AD FSM leave freeze enable
  [0] ADENTERFREEZEEN — AD FSM enter freeze enable
0x30C ADFSM22 ro
  [31:16] ADITLEAVESTATUS — AD FSM IT leave status
  [15:0] ADITENTERSTATUS — AD FSM IT enter status
0x310 ADFSM23
  [31:16] ADFSMCOND1ENC — AD next states
  [15:0] ADFSMCOND0ENC — AD next states
0x314 ADFSM24
  [31:16] ADFSMCOND3ENC — AD next states
  [15:0] ADFSMCOND2ENC — AD next states
0x318 ADFSM25
  [31:16] ADFSMCONDOR1 — AD FSM OR cond
  [15:0] ADFSMCONDOR0 — AD FSM OR cond
0x31C ADFSM26
  [31:16] ADFSMCOND1END — AD next states
  [15:0] ADFSMCOND0END — AD next states
0x320 ADFSM27
  [31:16] ADFSMCOND3END — AD next states
  [15:0] ADFSMCOND2END — AD next states
0x324 ADFSM28
  [31:16] ADORESTARTRXFORCE — AD next states
  [15:0] ADOSETANTFORCE — AD next states
0x328 ADFSM29
  [31:16] ADOQUALCLEARFORCE — AD next states
  [15:0] ADOQUALUPDATEFORCE — AD next states
0x32C ADFSM30
  [31:0] ADODEMODRXREQ — AD next states
0x330 ADPC1 reset 0x1200040
  [31:27] ADPCSKIPCHIPS — ADPC manual skip chip
  [26:24] ADPCWNDCNT — ADPC window cnt
  [23:16] ADPCTIMINGBAUDS
  [14:8] ADPCCORROFFSETCHIP — ADPC 1st window offset
  [7:1] ADPCWNDSIZECHIP — ADPC window size
  [0] ADPCEN — ADPC enable
0x334 ADPC2 reset 0xA0
  [29:27] ADPCWNDCNTRST — ADPC window cnt reset
  [26:19] ADPCSIGAMPTHR — ADPC signal amplitude THR
  [18] ADENCORR32 — ADPC enable correlators 16-31
    0=DISABLE (Disable corrleators 16-31); 1=ENABLE (Enable correlators 16-31)
  [17:10] ADPCPRETIMINGBAUDS — ADPC TIMINGBAUDS during PRE
  [9:0] ADPCCORRSAMPLES — ADPC correlation samples
0x338 ADPC3 reset 0x1005008
  [25] ADBBSSSELWRDATA — ADBBSS select RAM write data
    0=ADBBSS (Select adbbss compressed output for RAM write); 1=DATAFILTER (Select datafilter output for RAM write)
  [24] ADBBSSAVGFREEZE — ADBBSS average freeze
  [23:16] ADBBSSAVGWAIT — ADBBSS average wait
  [15:12] ADBBSSAMPEXP — ADBBSS amp exponent
  [11:8] ADBBSSAMPMANT — ADBBSS amp mantissa
  [7:5] ADBBSSAVGPER — ADBBSS average period
  [4] ADBBSSAVGEN — ADBBSS average enable
  [3:1] ADBBSSFILTLENGTH — ADBBSS filter length
  [0] ADBBSSEN — ADBBSS enable
0x33C ADPC4 reset 0x1F1F1F1F
  [8n+4:8n] ADBBSSAMPLUT{n} (n=0..3)
0x340 ADPC5 reset 0x1B1F1F1F
  [8n-28:8n-32] ADBBSSAMPLUT{n} (n=4..7)
0x344 ADPC6 reset 0x11131518
  [8n-60:8n-64] ADBBSSAMPLUT{n} (n=8..11)
0x348 ADPC7 reset 0xC0D0E10
  [8n-92:8n-96] ADBBSSAMPLUT{n} (n=12..15)
0x34C ADPC8 reset 0x2F87C145
  [31:22] ADPCANTSAMPSWITCH, [21:14] ADPCANTSAMPWRITE, [13:8] ADPCANTSAMPBUF, [6] ADPCANTSAMPSWITCHWAIT, [5:3] ADPCANTSAMPOFFSET, [2:0] ADPCOSR
0x350 ADPC9
  [24:21] ADBBSSDNTHR — BBSS decrease threshold
  [20:17] ADBBSSUPTHR — BBSS increase threshold
  [16] ADBBSSSYNCEN — Enable sync of BBSS
    0=DISABLE (Do not synchronize BBSS to antenna switching); 1=ENABLE (Synchronize BBSS to anetnna switching)
  [15:8] ADBBSSAMPTHR
  [7:0] ADBBSSAMPAVGLIM
0x354 ADPC10
  [16:13] ADBBSSCHGDNTHR
  [12:9] ADBBSSCHGUPTHR
  [8] ADBBSSCHANGEEN
    0=DISABLE (Disable BBSS change indicator); 1=ENABLE (Enable BBSS change indicator)
  [7:0] ADBBSSAMPJUMP
0x3B0 HADMCTRL0
  [31] SRC2AUTOSCALE — SRC2 Autoscaling Debug Output
  [30] SSAFCGEAR — SS AFC Gear SW
  [29] TXUPSAMPOSR4 — TX symbol UP Sampling by 4
  [28] PKTSENTSEL — RTT Packet Sent Selection
    0=BAUD_PRESENT (Use BAUD_PRESENT as indication of packet sent. Before modulator CDC); 1=MOD_PRESENT (Use MOD_PRESENT as indication of packet TX. After modulator CDC)
  [27:26] DFTSCALE — DFT INPUT Scale
  [14] AVGMODE — Averaging Mode
    0=PHASEAMP (Phase / amplitude polar averaging); 1=IQ (I,Q Cartesian averaging)
  [13:12] PM — Phase Measurement Time
  [5] RTTPHY — PHY Used for RTT Packets
  [4] ROLE — HADM Role
    0=INITIATOR (Device is the initiator); 1=REFLECTOR (Device is the reflector)
  [3] SNDSEQEN — Sounding Sequence Enable
  [2] PESEN — Packet Exchange Step Enable
  [1] TESEN — Tone Exchange Step Enable
  [0] HADMEN — Enable HADM
0x3B4 HADMCTRL1 reset 0x40000
  [31:22] AVGSTARTOFF — AVG Start Point Offset
  [18:15] MAXSCHWIN — SCH WINDOW SIZE
  [14:8] DFTSTARTOFF — DFT Start Point Offset
  [2:0] STEPSTATE — State for HADM HW to execute
    0=IDLE; 1=I_FREQ_COMP; 2=R_FREQ_COMP_FREQ_MEAS; 3=I_PES; 4=R_PES; 5=R_PES_TES; 6=R_TES; 7=I_TES
0x3B8 HADMSTATUS0 ro
  [31:16] AVG1 — Average 1
  [15:0] AVG0 — Average 0
0x3BC HADMSTATUS1 ro
  [31:16] TIMETOX — Time for ToX
  [15:0] FREQOFFSET — Frequency offset measurement
0x3C0 HADMSTATUS2 ro
  [29:20] COSTEARL1 — EARLY COST-1
  [19:10] COSTCURR1 — CURR COST-1
  [9:0] COSTLATE1 — LATE COST-1
0x3C4 HADMSTATUS3 ro
  [29:20] COSTEARL0 — EARLY COST-0
  [19:10] COSTCURR0 — CURR COST-0
  [9:0] COSTLATE0 — LATE COST-0
0x3C8 HADMSTATUS4 ro
  [30:16] SBSP500Q — Postive 500K Imag
  [14:0] SBSP500I — Postive 500K Real
0x3CC HADMSTATUS5 ro
  [30:16] SBSM500Q — Negtive 500K Imag
  [14:0] SBSM500I — Negtive 500K Real
0x3D0 HADMSTATUS6 ro
  [31:26] SBSMSCALE — Negative Frequency Scale
  [25:20] SBSPSCALE — Positive Frequency Scale
  [15:0] FREQMEAS — Frequency Compensation Measurement
0x3E0 SRC2NCOCTRL
  [14:1] PHASEPERCLK — Phase step per clock cycle
  [0] SRC2NCOEN — Enable SRC2 NCO supplemental clock
0x400 SPARE
  [7:0] SPARE
